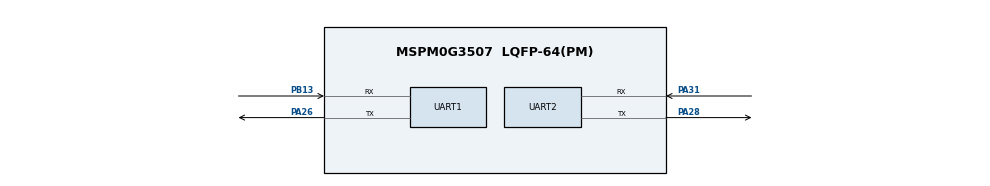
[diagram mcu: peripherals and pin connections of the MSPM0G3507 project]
/**
 * These arguments were used when this file was generated. They will be automatically applied on subsequent loads
 * via the GUI or CLI. Run CLI with '--help' for additional information on how to override these arguments.
 * @cliArgs --device "MSPM0G350X" --part "Default" --package "LQFP-64(PM)" --product "mspm0_sdk@2.10.00.04"
 * @v2CliArgs --device "MSPM0G3507" --package "LQFP-64(PM)" --product "mspm0_sdk@2.10.00.04"
 * @versions {"tool":"1.27.1+4634"}
 */

/**
 * Import the modules used in this configuration.
 */
const Board         = scripting.addModule("/ti/driverlib/Board");
const GPIO          = scripting.addModule("/ti/driverlib/GPIO", {}, false);
const GPIO1         = GPIO.addInstance();
const MATHACL       = scripting.addModule("/ti/driverlib/MATHACL");
const SYSCTL        = scripting.addModule("/ti/driverlib/SYSCTL");
const UART          = scripting.addModule("/ti/driverlib/UART", {}, false);
const UART1         = UART.addInstance();
const UART2         = UART.addInstance();
const ProjectConfig = scripting.addModule("/ti/project_config/ProjectConfig");

/**
 * Write custom configuration values to the imported modules.
 */
const divider9       = system.clockTree["UDIV"];
divider9.divideValue = 2;

const gate7  = system.clockTree["MFCLKGATE"];
gate7.enable = true;

const mux4       = system.clockTree["EXHFMUX"];
mux4.inputSelect = "EXHFMUX_XTAL";

const mux5       = system.clockTree["EXLFMUX"];
mux5.inputSelect = "EXLFMUX_XTAL";

const mux8       = system.clockTree["HSCLKMUX"];
mux8.inputSelect = "HSCLKMUX_SYSPLL2X";

const mux12       = system.clockTree["SYSPLLMUX"];
mux12.inputSelect = "zSYSPLLMUX_HFCLK";

const pinFunction4     = system.clockTree["HFXT"];
pinFunction4.enable    = true;
pinFunction4.inputFreq = 40;

const pinFunction6     = system.clockTree["LFXT"];
pinFunction6.enable    = true;
pinFunction6.inputFreq = 32.768;


GPIO1.port                               = "PORTB";
GPIO1.$name                              = "LED1";
GPIO1.associatedPins[0].internalResistor = "PULL_DOWN";
GPIO1.associatedPins[0].$name            = "PIN_22";
GPIO1.associatedPins[0].assignedPin      = "22";

SYSCTL.powerSysInterrupts = ["FLASH_SEC"];
SYSCTL.clockTreeEn        = true;

UART1.$name                            = "IMU";
UART1.targetBaudRate                   = 115200;
UART1.enabledInterrupts                = ["RX"];
UART1.peripheral.rxPin.$assign         = "PB13";
UART1.peripheral.txPin.$assign         = "PA26";
UART1.txPinConfig.$name                = "ti_driverlib_gpio_GPIOPinGeneric0";
UART1.txPinConfig.direction            = scripting.forceWrite("OUTPUT");
UART1.txPinConfig.hideOutputInversion  = scripting.forceWrite(false);
UART1.txPinConfig.onlyInternalResistor = scripting.forceWrite(false);
UART1.txPinConfig.passedPeripheralType = scripting.forceWrite("Digital");
UART1.rxPinConfig.$name                = "ti_driverlib_gpio_GPIOPinGeneric1";
UART1.rxPinConfig.hideOutputInversion  = scripting.forceWrite(false);
UART1.rxPinConfig.onlyInternalResistor = scripting.forceWrite(false);
UART1.rxPinConfig.passedPeripheralType = scripting.forceWrite("Digital");

UART2.$name                            = "PRINT";
UART2.targetBaudRate                   = 115200;
UART2.peripheral.rxPin.$assign         = "PA31";
UART2.peripheral.txPin.$assign         = "PA28";
UART2.txPinConfig.$name                = "ti_driverlib_gpio_GPIOPinGeneric2";
UART2.txPinConfig.direction            = scripting.forceWrite("OUTPUT");
UART2.txPinConfig.hideOutputInversion  = scripting.forceWrite(false);
UART2.txPinConfig.onlyInternalResistor = scripting.forceWrite(false);
UART2.txPinConfig.passedPeripheralType = scripting.forceWrite("Digital");
UART2.rxPinConfig.$name                = "ti_driverlib_gpio_GPIOPinGeneric3";
UART2.rxPinConfig.hideOutputInversion  = scripting.forceWrite(false);
UART2.rxPinConfig.onlyInternalResistor = scripting.forceWrite(false);
UART2.rxPinConfig.passedPeripheralType = scripting.forceWrite("Digital");

ProjectConfig.genLibDrivers = true;
ProjectConfig.genLinker     = false;
ProjectConfig.genStartup    = false;
ProjectConfig.genOpts       = false;
ProjectConfig.genLibs       = false;
scripting.suppress("All four File Generation options must be enabled in order to guarantee Device Migration support\\. If an option is disabled, the user must manually configure that setting on its own file\\.", ProjectConfig);

/**
 * Pinmux solution for unlocked pins/peripherals. This ensures that minor changes to the automatic solver in a future
 * version of the tool will not impact the pinmux you originally saw.  These lines can be completely deleted in order to
 * re-solve from scratch.
 */
pinFunction4.peripheral.$suggestSolution           = "SYSCTL";
pinFunction4.peripheral.hfxInPin.$suggestSolution  = "PA5";
pinFunction4.peripheral.hfxOutPin.$suggestSolution = "PA6";
pinFunction6.peripheral.$suggestSolution           = "SYSCTL";
pinFunction6.peripheral.lfxInPin.$suggestSolution  = "PA3";
pinFunction6.peripheral.lfxOutPin.$suggestSolution = "PA4";
Board.peripheral.$suggestSolution                  = "DEBUGSS";
Board.peripheral.swclkPin.$suggestSolution         = "PA20";
Board.peripheral.swdioPin.$suggestSolution         = "PA19";
GPIO1.associatedPins[0].pin.$suggestSolution       = "PB22";
UART1.peripheral.$suggestSolution                  = "UART3";
UART2.peripheral.$suggestSolution                  = "UART0";
